# nrf7120_enga_flpr register map
Vendor: Nordic Semiconductor; Series: nrf71; File version: 1
Registers are 32-bit, read-write, reset 0x0 unless marked. A register's access mark holds for its fields unless they carry their own. Offsets are from the block's base; [hi:lo] are bit positions; lines under a group give offsets from that group; 'fields as' and 'values as' point back to an identical list.

## GLOBAL_LFRC_NS — LFRC peripheral 0
Base 0x40123000
Same registers: GLOBAL_LFRC_S 0x50123000
0x00 TASKS_CAL wo — Start the calibration of RC oscillator
  [0] TASKS_CAL
    1=Trigger task
0x04 TASKS_CANCELCAL wo — Cancel the calibration
  [0] TASKS_CANCELCAL
    1=Trigger task
0x100 EVENTS_CALDONE — Calibration done
  [0] EVENTS_CALDONE
    0=NotGenerated (Event not generated); 1=Generated (Event generated)
0x104 EVENTS_TRIMDONE — Trim done
  [0] EVENTS_TRIMDONE
    values as EVENTS_CALDONE.EVENTS_CALDONE
0x108 EVENTS_TRIMERROR — Trim error
  [0] EVENTS_TRIMERROR
    values as EVENTS_CALDONE.EVENTS_CALDONE
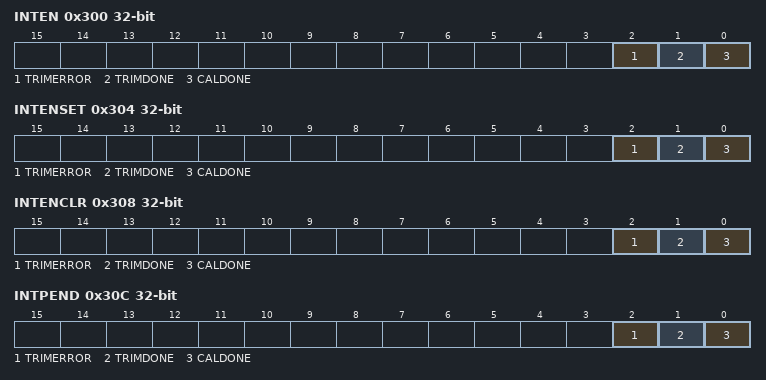
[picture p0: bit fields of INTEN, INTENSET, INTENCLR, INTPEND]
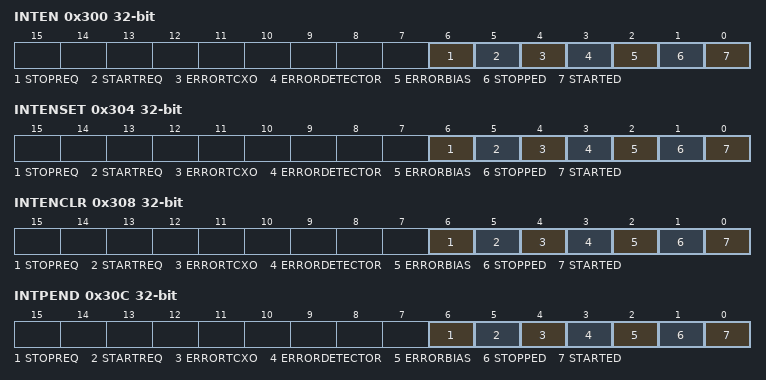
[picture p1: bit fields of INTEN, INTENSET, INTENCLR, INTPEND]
0x300 INTEN — Enable or disable interrupt
  [all] fields
    0=Disabled; 1=Enabled
  [2] TRIMERROR — Enable or disable interrupt for event TRIMERROR
  [1] TRIMDONE — Enable or disable interrupt for event TRIMDONE
  [0] CALDONE — Enable or disable interrupt for event CALDONE
0x304 INTENSET — Enable interrupt
  [all] fields
    on read: 0=Disabled (Read: Disabled); 1=Enabled (Read: Enabled) | on write: 1=Set (Enable)
  [2] TRIMERROR — Write '1' to enable interrupt for event TRIMERROR
  [1] TRIMDONE — Write '1' to enable interrupt for event TRIMDONE
  [0] CALDONE — Write '1' to enable interrupt for event CALDONE
0x308 INTENCLR — Disable interrupt
  [all] fields
    on read: 0=Disabled (Read: Disabled); 1=Enabled (Read: Enabled) | on write: 1=Clear (Disable)
  [2] TRIMERROR — Write '1' to disable interrupt for event TRIMERROR
  [1] TRIMDONE — Write '1' to disable interrupt for event TRIMDONE
  [0] CALDONE — Write '1' to disable interrupt for event CALDONE
0x30C INTPEND ro — Pending interrupts
  [all] fields
    on read: 0=NotPending (Read: Not pending); 1=Pending (Read: Pending)
  [2] TRIMERROR — Read pending status of interrupt for event TRIMERROR
  [1] TRIMDONE — Read pending status of interrupt for event TRIMDONE
  [0] CALDONE — Read pending status of interrupt for event CALDONE
0x420 CAL group — Unspecified
  0x00 LENGTH reset 0x2 — Measurement cycle count length used while calibration
    [2:0] LENGTH — Number of cycles
      0=N64 (64 cycles); 1=N128 (128 cycles); 2=N256 (256 cycles); 3=N512 (512 cycles)

## GLOBAL_HFXO64M_NS — HFXO64M peripheral 0
Base 0x40124000
Same registers: GLOBAL_HFXO64M_S 0x50124000
0x100 EVENTS_STARTED — HFXO64M started
  [0] EVENTS_STARTED
    0=NotGenerated (Event not generated); 1=Generated (Event generated)
0x104 EVENTS_STOPPED — HFXO64M stopped
  [0] EVENTS_STOPPED
    values as EVENTS_STARTED.EVENTS_STARTED
0x108 EVENTS_ERRORBIAS — Error with BIAS setup
  [0] EVENTS_ERRORBIAS
    values as EVENTS_STARTED.EVENTS_STARTED
0x10C EVENTS_ERRORDETECTOR — Error with DETECTOR
  [0] EVENTS_ERRORDETECTOR
    values as EVENTS_STARTED.EVENTS_STARTED
0x110 EVENTS_ERRORTCXO — Error with TCXO startup
  [0] EVENTS_ERRORTCXO
    values as EVENTS_STARTED.EVENTS_STARTED
0x114 EVENTS_STARTREQ — Clock start has been requested
  [0] EVENTS_STARTREQ
    values as EVENTS_STARTED.EVENTS_STARTED
0x118 EVENTS_STOPREQ — Clock stop has been requested
  [0] EVENTS_STOPREQ
    values as EVENTS_STARTED.EVENTS_STARTED
0x300 INTEN — Enable or disable interrupt
  [all] fields
    0=Disabled; 1=Enabled
  [6] STOPREQ — Enable or disable interrupt for event STOPREQ
  [5] STARTREQ — Enable or disable interrupt for event STARTREQ
  [4] ERRORTCXO — Enable or disable interrupt for event ERRORTCXO
  [3] ERRORDETECTOR — Enable or disable interrupt for event ERRORDETECTOR
  [2] ERRORBIAS — Enable or disable interrupt for event ERRORBIAS
  [1] STOPPED — Enable or disable interrupt for event STOPPED
  [0] STARTED — Enable or disable interrupt for event STARTED
0x304 INTENSET — Enable interrupt
  [all] fields
    on read: 0=Disabled (Read: Disabled); 1=Enabled (Read: Enabled) | on write: 1=Set (Enable)
  [6] STOPREQ — Write '1' to enable interrupt for event STOPREQ
  [5] STARTREQ — Write '1' to enable interrupt for event STARTREQ
  [4] ERRORTCXO — Write '1' to enable interrupt for event ERRORTCXO
  [3] ERRORDETECTOR — Write '1' to enable interrupt for event ERRORDETECTOR
  [2] ERRORBIAS — Write '1' to enable interrupt for event ERRORBIAS
  [1] STOPPED — Write '1' to enable interrupt for event STOPPED
  [0] STARTED — Write '1' to enable interrupt for event STARTED
0x308 INTENCLR — Disable interrupt
  [all] fields
    on read: 0=Disabled (Read: Disabled); 1=Enabled (Read: Enabled) | on write: 1=Clear (Disable)
  [6] STOPREQ — Write '1' to disable interrupt for event STOPREQ
  [5] STARTREQ — Write '1' to disable interrupt for event STARTREQ
  [4] ERRORTCXO — Write '1' to disable interrupt for event ERRORTCXO
  [3] ERRORDETECTOR — Write '1' to disable interrupt for event ERRORDETECTOR
  [2] ERRORBIAS — Write '1' to disable interrupt for event ERRORBIAS
  [1] STOPPED — Write '1' to disable interrupt for event STOPPED
  [0] STARTED — Write '1' to disable interrupt for event STARTED
0x30C INTPEND ro — Pending interrupts
  [all] fields
    on read: 0=NotPending (Read: Not pending); 1=Pending (Read: Pending)
  [6] STOPREQ — Read pending status of interrupt for event STOPREQ
  [5] STARTREQ — Read pending status of interrupt for event STARTREQ
  [4] ERRORTCXO — Read pending status of interrupt for event ERRORTCXO
  [3] ERRORDETECTOR — Read pending status of interrupt for event ERRORDETECTOR
  [2] ERRORBIAS — Read pending status of interrupt for event ERRORBIAS
  [1] STOPPED — Read pending status of interrupt for event STOPPED
  [0] STARTED — Read pending status of interrupt for event STARTED

## GLOBAL_OSCRFR_NS — OSCRFR peripheral 0
Base 0x4012A000
Same registers: GLOBAL_OSCRFR_S 0x5012A000

## GLOBAL_AUDIOPLLM_NS — AUXPM 0
Base 0x40130000
Same registers: GLOBAL_AUDIOPLLM_S 0x50130000
